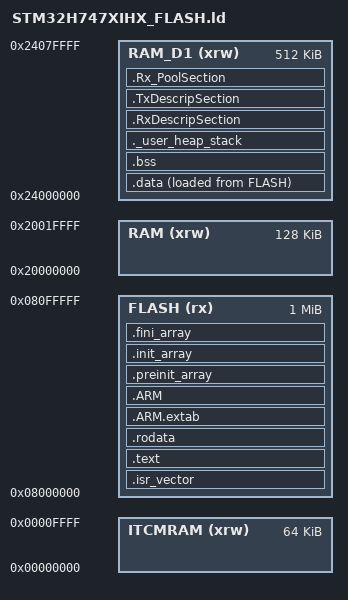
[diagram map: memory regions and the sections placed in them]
/*
******************************************************************************
**

**  File        : LinkerScript.ld
**
**
**  Abstract    : Linker script for STM32H7 series
**                1024Kbytes FLASH and 192Kbytes RAM
**
**                Set heap size, stack size and stack location according
**                to application requirements.
**
**                Set memory bank area and size if external memory is used.
**
**  Target      : STMicroelectronics STM32
**
**  Distribution: The file is distributed as is, without any warranty
**                of any kind.
**
*****************************************************************************
** @attention
**
** Copyright (c) 2019 STMicroelectronics.
** All rights reserved.
**
** This software is licensed under terms that can be found in the LICENSE file
** in the root directory of this software component.
** If no LICENSE file comes with this software, it is provided AS-IS.
**
******************************************************************************
*/

/* Entry Point */
ENTRY(Reset_Handler)

/* Highest address of the user mode stack - in RAM_D1 (AXI SRAM), not DTCM,
   so everything the Ethernet DMA needs to reach (lwIP's packet memory
   included, not just its own descriptors) lives in memory the DMA can
   actually see. See the .data/.bss placement below and MPU_Config() in
   main.c, which marks this whole region non-cacheable. */
_estack = ORIGIN(RAM_D1) + LENGTH(RAM_D1);
/* Generate a link error if heap and stack don't fit into RAM */
_Min_Heap_Size = 0x400 ;      /* required amount of heap  */
_Min_Stack_Size = 0x2000 ; /* required amount of stack */

/* Specify the memory areas */
MEMORY
{
FLASH (rx)      : ORIGIN = 0x08000000, LENGTH = 1024K
RAM (xrw)      : ORIGIN = 0x20000000, LENGTH = 128K
ITCMRAM (xrw)      : ORIGIN = 0x00000000, LENGTH = 64K
RAM_D1 (xrw)      : ORIGIN = 0x24000000, LENGTH = 512K
}

/* Define output sections */
SECTIONS
{
  /* The startup code goes first into FLASH */
  .isr_vector :
  {
    . = ALIGN(4);
    KEEP(*(.isr_vector)) /* Startup code */
    . = ALIGN(4);
  } >FLASH

  /* The program code and other data goes into FLASH */
  .text :
  {
    . = ALIGN(4);
    *(.text)           /* .text sections (code) */
    *(.text*)          /* .text* sections (code) */
    *(.glue_7)         /* glue arm to thumb code */
    *(.glue_7t)        /* glue thumb to arm code */
    *(.eh_frame)

    KEEP (*(.init))
    KEEP (*(.fini))

    . = ALIGN(4);
    _etext = .;        /* define a global symbols at end of code */
  } >FLASH

  /* Constant data goes into FLASH */
  .rodata :
  {
    . = ALIGN(4);
    *(.rodata)         /* .rodata sections (constants, strings, etc.) */
    *(.rodata*)        /* .rodata* sections (constants, strings, etc.) */
    . = ALIGN(4);
  } >FLASH

  .ARM.extab (READONLY) : /* The READONLY keyword is only supported in GCC11 and later, remove it if using GCC10 or earlier. */
  {
    *(.ARM.extab* .gnu.linkonce.armextab.*)
  } >FLASH
  .ARM (READONLY) : /* The READONLY keyword is only supported in GCC11 and later, remove it if using GCC10 or earlier. */
  {
    __exidx_start = .;
    *(.ARM.exidx*)
    __exidx_end = .;
  } >FLASH

  .preinit_array (READONLY) : /* The READONLY keyword is only supported in GCC11 and later, remove it if using GCC10 or earlier. */
  {
    PROVIDE_HIDDEN (__preinit_array_start = .);
    KEEP (*(.preinit_array*))
    PROVIDE_HIDDEN (__preinit_array_end = .);
  } >FLASH
  .init_array (READONLY) : /* The READONLY keyword is only supported in GCC11 and later, remove it if using GCC10 or earlier. */
  {
    PROVIDE_HIDDEN (__init_array_start = .);
    KEEP (*(SORT(.init_array.*)))
    KEEP (*(.init_array*))
    PROVIDE_HIDDEN (__init_array_end = .);
  } >FLASH
  .fini_array (READONLY) : /* The READONLY keyword is only supported in GCC11 and later, remove it if using GCC10 or earlier. */
  {
    PROVIDE_HIDDEN (__fini_array_start = .);
    KEEP (*(SORT(.fini_array.*)))
    KEEP (*(.fini_array*))
    PROVIDE_HIDDEN (__fini_array_end = .);
  } >FLASH

  /* used by the startup to initialize data */
  _sidata = LOADADDR(.data);

  /* Initialized data sections goes into RAM, load LMA copy after code */
  .data : 
  {
    . = ALIGN(4);
    _sdata = .;        /* create a global symbol at data start */
    *(.data)           /* .data sections */
    *(.data*)          /* .data* sections */

    . = ALIGN(4);
    _edata = .;        /* define a global symbol at data end */
  } >RAM_D1 AT> FLASH


  /* Uninitialized data section */
  . = ALIGN(4);
  .bss :
  {
    /* This is used by the startup in order to initialize the .bss section */
    _sbss = .;         /* define a global symbol at bss start */
    __bss_start__ = _sbss;
    *(.bss)
    *(.bss*)
    *(COMMON)

    . = ALIGN(4);
    _ebss = .;         /* define a global symbol at bss end */
    __bss_end__ = _ebss;
  } >RAM_D1

  /* User_heap_stack section, used to check that there is enough RAM left */
  ._user_heap_stack :
  {
    . = ALIGN(8);
    PROVIDE ( end = . );
    PROVIDE ( _end = . );
    . = . + _Min_Heap_Size;
    . = . + _Min_Stack_Size;
    . = ALIGN(8);
  } >RAM_D1

  /* Ethernet DMA descriptors and the zero-copy RX buffer pool (ethernetif.c)
     must live where the Ethernet DMA controller can actually reach them.
     "RAM" above is DTCM (0x20000000) - CPU-core-only, not on the system bus,
     so any bus master other than the CPU (like ETH DMA) cannot see it. RAM_D1
     is AXI SRAM, which is on the system bus, so it works for this. It still
     sits behind the D-Cache, so MPU_Config() in main.c marks this range
     non-cacheable to keep the CPU and the ETH DMA seeing the same bytes. */
  .RxDescripSection :
  {
    . = ALIGN(32);
    *(.RxDescripSection)
    . = ALIGN(32);
  } >RAM_D1

  .TxDescripSection :
  {
    . = ALIGN(32);
    *(.TxDescripSection)
    . = ALIGN(32);
  } >RAM_D1

  .Rx_PoolSection :
  {
    . = ALIGN(32);
    *(.Rx_PoolSection)
    . = ALIGN(32);
  } >RAM_D1

  /* Remove information from the standard libraries */
  /DISCARD/ :
  {
    libc.a ( * )
    libm.a ( * )
    libgcc.a ( * )
  }

  .ARM.attributes 0 : { *(.ARM.attributes) }
}


